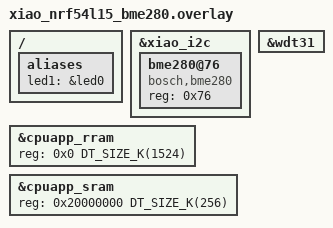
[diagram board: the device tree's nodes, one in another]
/*
 * XIAO nRF54L15 + Grove BME280 on the XIAO I2C connector.
 *
 * Grove BME280 modules are commonly strapped to 0x76. If the connected sensor
 * is strapped to 0x77, change the node name and reg value below to 77.
 */

/ {
	aliases {
		led1 = &led0;
	};
};

&xiao_i2c {
	status = "okay";

	bme280@76 {
		compatible = "bosch,bme280";
		reg = <0x76>;
		status = "okay";
	};
};

&cpuapp_rram {
	reg = <0x0 DT_SIZE_K(1524)>;
};

&cpuapp_sram {
	reg = <0x20000000 DT_SIZE_K(256)>;
	ranges = <0x0 0x20000000 0x40000>;
};

&wdt31 {
	status = "okay";
};
